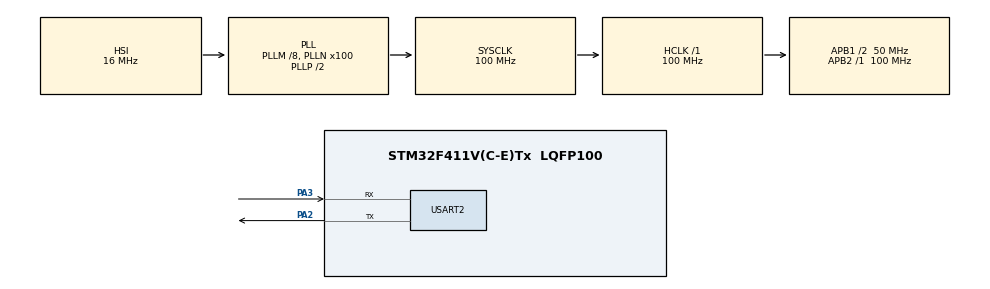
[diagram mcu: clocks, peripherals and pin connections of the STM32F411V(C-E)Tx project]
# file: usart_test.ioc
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Mcu.Family=STM32F4
RCC.CortexFreq_Value=100000000
RCC.APB1CLKDivider=RCC_HCLK_DIV2
NVIC.USART2_IRQn=true\:0\:0\:false\:false\:true\:true\:true
RCC.SYSCLKSource=RCC_SYSCLKSOURCE_PLLCLK
ProjectManager.StackSize=0x400
PA3.Mode=Asynchronous
ProjectManager.TargetToolchain=Makefile
RCC.HCLKFreq_Value=100000000
RCC.APB2TimFreq_Value=100000000
RCC.LSE_VALUE=32768
RCC.AHBFreq_Value=100000000
RCC.HSE_VALUE=25000000
board=custom
RCC.VCOOutputFreq_Value=200000000
RCC.APB2Freq_Value=100000000
Mcu.Name=STM32F411V(C-E)Tx
PA2.Signal=USART2_TX
RCC.48MHZClocksFreq_Value=50000000
RCC.SYSCLKFreq_VALUE=100000000
Mcu.Package=LQFP100
USART2.VirtualMode=VM_ASYNC
ProjectManager.HeapSize=0x200
RCC.HSI_VALUE=16000000
NVIC.PriorityGroup=NVIC_PRIORITYGROUP_4
RCC.PLLM=8
RCC.PLLN=100
RCC.APB1TimFreq_Value=100000000
PA2.Mode=Asynchronous
RCC.APB1Freq_Value=50000000
PA3.Signal=USART2_RX

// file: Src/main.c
/* USER CODE BEGIN Header */
/**
  ******************************************************************************
  * @file           : main.c
  * @brief          : Main program body
  ******************************************************************************
  * @attention
  *
  * <h2><center>&copy; Copyright (c) 2020 STMicroelectronics.
  * All rights reserved.</center></h2>
  *
  * This software component is licensed by ST under BSD 3-Clause license,
  * the "License"; You may not use this file except in compliance with the
  * License. You may obtain a copy of the License at:
  *                        opensource.org/licenses/BSD-3-Clause
  *
  ******************************************************************************
  */
/* USER CODE END Header */

#include "main.h"

/* USER CODE BEGIN Includes */
#include <stdio.h>
#include <stddef.h>
#include <stdint.h>
#include <stdbool.h>
#include <string.h>
/* USER CODE END Includes */

UART_HandleTypeDef huart2;

void SystemClock_Config(void);
static void MX_GPIO_Init(void);
static void MX_USART2_UART_Init(void);

/* USER CODE BEGIN 0 */

#define BUF_SIZE 10

volatile static bool uart2_ready;

size_t uart2_get_string(uint8_t *buf, size_t max_size)
{
  uint8_t c;
  size_t count;

  for (count = 0; count < max_size - 2; count++) {
    HAL_UART_Receive_IT(&huart2, &c, 1);
    while (!uart2_ready);
    uart2_ready = false;
    buf[count] = c;
    if (c == '\n') {
      buf[count + 1] = '\0';
      return count;
    }
    else {
    }
  }
  buf[count + 1] = '\n';
  buf[count + 2] = '\0';

  return count;
}

/* USER CODE END 0 */

int main(void)
{

  /* MCU Configuration--------------------------------------------------------*/

  /* Reset of all peripherals, Initializes the Flash interface and the Systick. */
  HAL_Init();

  /* Configure the system clock */
  SystemClock_Config();

  /* Initialize all configured peripherals */
  MX_GPIO_Init();
  MX_USART2_UART_Init();
  /* USER CODE BEGIN 2 */

  static uint8_t str1[] = "Hello, World!\n";
  static uint8_t buf[BUF_SIZE];
  static uint8_t buf2[BUF_SIZE];
  size_t n;

  HAL_UART_Transmit(&huart2, str1, sizeof(str1), 10000);

  /* USER CODE END 2 */

  /* Infinite loop */
  /* USER CODE BEGIN WHILE */
  while (1) {

    n = uart2_get_string(buf, BUF_SIZE);
    HAL_UART_Transmit(&huart2, buf, n, 10000);

    snprintf(buf2, BUF_SIZE, " %u\n", n);
    HAL_UART_Transmit(&huart2, buf2, strlen(buf2), 10000);

    /* USER CODE END WHILE */

  }
}

void SystemClock_Config(void)
{
  RCC_OscInitTypeDef RCC_OscInitStruct = {0};
  RCC_ClkInitTypeDef RCC_ClkInitStruct = {0};

  /** Configure the main internal regulator output voltage
  */
  __HAL_RCC_PWR_CLK_ENABLE();
  __HAL_PWR_VOLTAGESCALING_CONFIG(PWR_REGULATOR_VOLTAGE_SCALE1);
  /** Initializes the CPU, AHB and APB busses clocks
  */
  RCC_OscInitStruct.OscillatorType = RCC_OSCILLATORTYPE_HSI;
  RCC_OscInitStruct.HSIState = RCC_HSI_ON;
  RCC_OscInitStruct.HSICalibrationValue = RCC_HSICALIBRATION_DEFAULT;
  RCC_OscInitStruct.PLL.PLLState = RCC_PLL_ON;
  RCC_OscInitStruct.PLL.PLLSource = RCC_PLLSOURCE_HSI;
  RCC_OscInitStruct.PLL.PLLM = 8;
  RCC_OscInitStruct.PLL.PLLN = 100;
  RCC_OscInitStruct.PLL.PLLP = RCC_PLLP_DIV2;
  RCC_OscInitStruct.PLL.PLLQ = 4;
  if (HAL_RCC_OscConfig(&RCC_OscInitStruct) != HAL_OK)
  {
    Error_Handler();
  }
  /** Initializes the CPU, AHB and APB busses clocks
  */
  RCC_ClkInitStruct.ClockType = RCC_CLOCKTYPE_HCLK|RCC_CLOCKTYPE_SYSCLK
                              |RCC_CLOCKTYPE_PCLK1|RCC_CLOCKTYPE_PCLK2;
  RCC_ClkInitStruct.SYSCLKSource = RCC_SYSCLKSOURCE_PLLCLK;
  RCC_ClkInitStruct.AHBCLKDivider = RCC_SYSCLK_DIV1;
  RCC_ClkInitStruct.APB1CLKDivider = RCC_HCLK_DIV2;
  RCC_ClkInitStruct.APB2CLKDivider = RCC_HCLK_DIV1;

  if (HAL_RCC_ClockConfig(&RCC_ClkInitStruct, FLASH_LATENCY_3) != HAL_OK)
  {
    Error_Handler();
  }
}

static void MX_USART2_UART_Init(void)
{

  huart2.Instance = USART2;
  huart2.Init.BaudRate = 115200;
  huart2.Init.WordLength = UART_WORDLENGTH_8B;
  huart2.Init.StopBits = UART_STOPBITS_1;
  huart2.Init.Parity = UART_PARITY_NONE;
  huart2.Init.Mode = UART_MODE_TX_RX;
  huart2.Init.HwFlowCtl = UART_HWCONTROL_NONE;
  huart2.Init.OverSampling = UART_OVERSAMPLING_16;
  if (HAL_UART_Init(&huart2) != HAL_OK)
  {
    Error_Handler();
  }

}

static void MX_GPIO_Init(void)
{

  /* GPIO Ports Clock Enable */
  __HAL_RCC_GPIOA_CLK_ENABLE();

}

/* USER CODE BEGIN 4 */
void HAL_UART_RxCpltCallback(UART_HandleTypeDef *uart) {
  uart2_ready = true;
}

/* USER CODE END 4 */

void Error_Handler(void)
{
}

/************************ (C) COPYRIGHT STMicroelectronics *****END OF FILE****/
